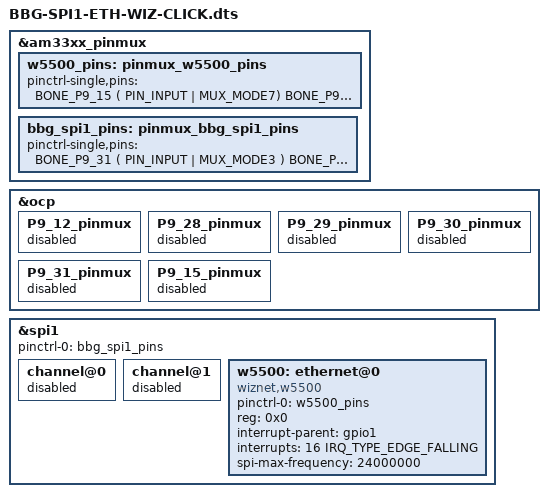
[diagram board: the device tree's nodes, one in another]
/*
 * Copyright (C) 2017 Robert Nelson <robertcnelson@gmail.com>
 *
 * This program is free software; you can redistribute it and/or modify
 * it under the terms of the GNU General Public License version 2 as
 * published by the Free Software Foundation.
 */

/*
 * Changes by Eric Felix <eric@modio.se>
 * 
 * The pinout for all signals have been changed from
 * being PocketBeagle compatible to being BeagleBone Green
 * compatible.
 * COPYRIGHT (C) MODIO AB 2018
 */

/dts-v1/;
/plugin/;

#include <dt-bindings/board/am335x-bbw-bbb-base.h>
#include <dt-bindings/gpio/gpio.h>
#include <dt-bindings/pinctrl/am33xx.h>
#include <dt-bindings/interrupt-controller/irq.h>

/ {
        fragment@0 {
                target = <&am33xx_pinmux>;
                __overlay__ {

                        w5500_pins: pinmux_w5500_pins {
                                pinctrl-single,pins = <
                                        BONE_P9_15 ( PIN_INPUT | MUX_MODE7) /* INT */
                                        BONE_P9_12 ( PIN_OUTPUT_PULLUP | MUX_MODE7 ) /* RESET */
                                >;
                        };

                        bbg_spi1_pins: pinmux_bbg_spi1_pins {
                                pinctrl-single,pins = <
                                        BONE_P9_31 ( PIN_INPUT | MUX_MODE3 ) /* SCLK */
                                        BONE_P9_29 ( PIN_INPUT | MUX_MODE3 ) /* D0 */
                                        BONE_P9_30 ( PIN_INPUT | MUX_MODE3 ) /* D1 */
                                        BONE_P9_28 ( PIN_INPUT | MUX_MODE3 ) /* CS0 */
                                >;
                        };
                };
        };
/*
 * Pin mapping
 * P9_12 -> RESET P9_15 -> INT P9_31 -> SCLK
 * P9_29 -> D0    P9_30 -> D1  P9_28 -> CS0
 */     
        fragment@1 {
                target = <&ocp>;
                __overlay__ {

                        P9_12_pinmux {
                                status = "disabled";
                        };
                        P9_28_pinmux {
                                status = "disabled";
                        };
                        P9_29_pinmux {
                                status = "disabled";
                        };
                        P9_30_pinmux {
                                status = "disabled";
                        };
                        P9_31_pinmux {
                                status = "disabled";
                        };
                        P9_15_pinmux {
                                status = "disabled";
                        };
                };
        };

        fragment@2 {
                target = <&spi1>;
                __overlay__ {

                        status = "okay";
                        pinctrl-names = "default";
                        pinctrl-0 = <&bbg_spi1_pins>;

                        #address-cells = <1>; /* number of cells required to define a chip select addres on the SPI bus */
                        #size-cells = <0>; /* Should be zero */

                        channel@0 {
                                status = "disabled"; /* Enabled by default in bb-kernel so users can use spidev from userspace */
                        };
                        channel@1 {
                                status = "disabled";
                        };

                        w5500: ethernet@0 {
                                compatible = "wiznet,w5500";
                                pinctrl-names = "default";
                                pinctrl-0 = <&w5500_pins>;
                                reg = <0x0>; /* chip select addres of device */
                                interrupt-parent = <&gpio1>; /* Should match the chosen gpio interrupt group */
                                interrupts = <16 IRQ_TYPE_EDGE_FALLING>; /* same as x in gpioY[x], see table http://exploringbeaglebone.com/wp-content/uploads/resources/BBBP9Header.pdf */
                                spi-max-frequency = <24000000>;
                        };
                };
        };
};
